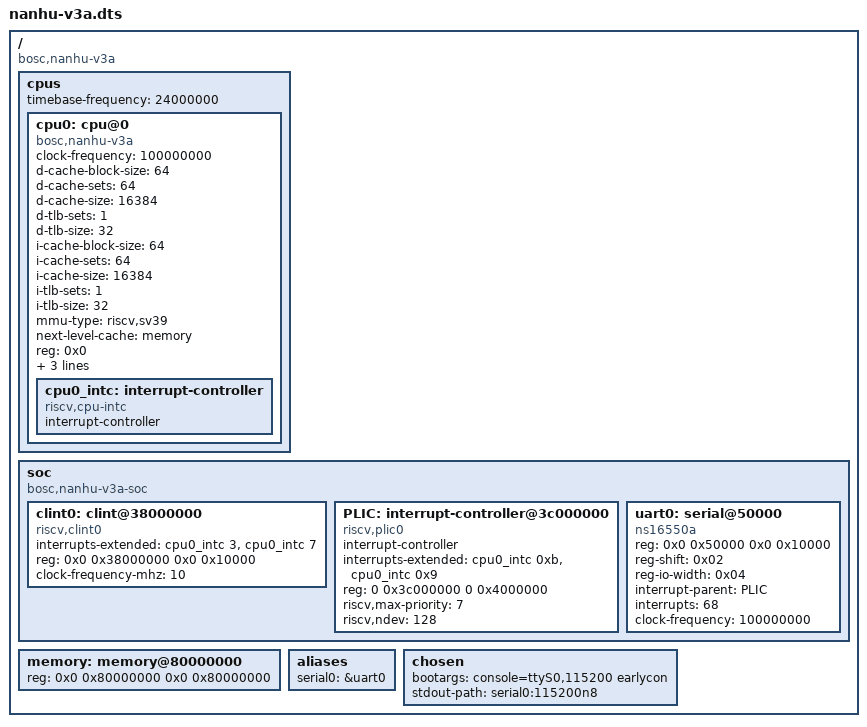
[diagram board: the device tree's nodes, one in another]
// SPDX-License-Identifier: (GPL-2.0 OR MIT)
/* Copyright (c) 2023-2024 BOSC */

/dts-v1/;

/ {
	#address-cells = <2>;
	#size-cells = <2>;
	compatible = "bosc,nanhu-v3a";

	cpus {
		#address-cells = <1>;
		#size-cells = <0>;
		timebase-frequency = <24000000>;//rtc is 1M

		cpu0: cpu@0 {
			clock-frequency = <100000000>;
			compatible = "bosc,nanhu-v3a", "riscv";
			d-cache-block-size = <64>;
			d-cache-sets = <64>;
			d-cache-size = <16384>;
			d-tlb-sets = <1>;
			d-tlb-size = <32>;
			device_type = "cpu";
			i-cache-block-size = <64>;
			i-cache-sets = <64>;
			i-cache-size = <16384>;
			i-tlb-sets = <1>;
			i-tlb-size = <32>;
			mmu-type = "riscv,sv39";
			next-level-cache = <&memory>;
			reg = <0x0>;
			riscv,isa = "rv64imafdcv";
			status = "okay";
			timebase-frequency = <24000000>;//rtc is 1M
			tlb-split;

			cpu0_intc: interrupt-controller {
				#interrupt-cells = <1>;
				compatible = "riscv,cpu-intc";
				interrupt-controller;
			};
		};

	//	cpu1: cpu@1 {
	//		clock-frequency = <0>;
	//		compatible = "bosc,nanhu-v3a", "riscv";
	//		d-cache-block-size = <64>;
	//		d-cache-sets = <64>;
	//		d-cache-size = <16384>;
	//		d-tlb-sets = <1>;
	//		d-tlb-size = <32>;
	//		device_type = "cpu";
	//		i-cache-block-size = <64>;
	//		i-cache-sets = <64>;
	//		i-cache-size = <16384>;
	//		i-tlb-sets = <1>;
	//		i-tlb-size = <32>;
	//		mmu-type = "riscv,sv39";
	//		next-level-cache = <&memory>;
	//		reg = <0x1>;
	//		riscv,isa = "rv64imafdc";
	//		status = "okay";
	//		timebase-frequency = <100000000>;//rtc is 1M
	//		tlb-split;

	//		cpu1_intc: interrupt-controller {
	//			#interrupt-cells = <1>;
	//			compatible = "riscv,cpu-intc";
	//			interrupt-controller;
	//		};
	//	};

	};

	soc {
		#address-cells = <2>;
		#size-cells = <2>;
		compatible = "bosc,nanhu-v3a-soc", "simple-bus";
		ranges;

		//debug_controller0: debug-controller@0 {
		//	compatible = "sifive,debug-013", "riscv,debug-013";
		//	interrupts-extended = <&cpu0_intc 65535>;
		//	reg = <0x0 0x0 0x0 0x1000>;
		//	reg-names = "control";
		//};

		clint0: clint@38000000 {
			compatible = "riscv,clint0";
			//interrupts-extended = <&cpu0_intc 3 &cpu0_intc 7 &cpu1_intc 3 &cpu1_intc 7>;
			interrupts-extended = <&cpu0_intc 3 &cpu0_intc 7>;
			reg = <0x0 0x38000000 0x0 0x10000>;
			reg-names = "control";
			clock-frequency-mhz = <10>;
		};

		PLIC: interrupt-controller@3c000000 {
			#interrupt-cells = <1>;
			compatible = "riscv,plic0";
			interrupt-controller;
			interrupts-extended = <&cpu0_intc 0xb &cpu0_intc 0x9>;
			reg = <0 0x3c000000 0 0x4000000>;
			reg-names = "control";
			riscv,max-priority = <7>;
			riscv,ndev = <128>;
		};

		// clkc: misc_clk_0 {
		// 	#clock-cells = <0>;
		// 	clock-frequency = <100000000>;
		// 	compatible = "fixed-clock";
		// };
		// clkb: misc_clk_1 {
		// 	#clock-cells = <0>;
		// 	clock-frequency = <25000000>;
		// 	compatible = "fixed-clock";
		// };
                  
                // ethernet1: ethernet@190000 {
                //         compatible = "st,stm32-dwmac", "snps,dwmac-3.50a";
                //         reg = <0 0x190000 0 0x10000>;
                //         reg-names = "stmmaceth";
                //         interrupt-parent = <&PLIC>;
                //         interrupts = <76 75 74>;
                //         interrupt-names = "eth_lpi", "macirq", "eth_wake_irq";
                //         clock-names = "stmmaceth";
                //         clocks = <&clkc>;
                //         //st,syscon = <&syscfg 0x4>;
                //         snps,pbl = <2>;
                //         snps,mixed-burst;
                //         phy-mode = "rgmii";
                //         // stmmac driver can not find phy if add this node
                //         //
                //         phy-handle = <&phy>;
                //             mdio {
                //                 #address-cells = <0x1>;
                //                 #size-cells = <0x0>;
                //                 phyaddr = <0x0>;
                //                 compatible = "snps,dwmac-mdio";
                //                 phy: phy@0 {
                //                 //phyaddr = <0x7>;
                //                 compatible = "marvell,88e1510";
                //                 device_type = "ethernet-phy";
                //                 reg = <0x0>;
                //             };
                //         };
                // };


        // sdhci2: sdhci@1200000 {
        //     compatible = "snps,dwcmshc-sdhci";
        //     reg = <0 0x1200000 0 0x10000>;
        //     interrupt-parent = <&PLIC>;
        //     interrupts = <77>;
        //     clocks = <&clkb>;
        //     clock-names = "core";
        //     sd-uhs-sdr12;
        //     no-1-8-v;
        //     disable-wp;
        //     broken-cd;
        //     bus-width = <4>;
        // };


		uart0: serial@50000 {
			compatible = "ns16550a";
			reg = <0x0 0x50000 0x0 0x10000>;
			reg-shift = <0x02>;
			reg-io-width = <0x04>;
			interrupt-parent = <&PLIC>;
			interrupts = <68>;
			clock-frequency = <100000000>;
			status = "okay";
		};
	};

	memory: memory@80000000 {
		device_type = "memory";
		reg = <0x0 0x80000000 0x0 0x80000000>;
	};
	aliases {
		serial0 = &uart0;
	};

	chosen {
		//bootargs = "root=/dev/nvme0n1p2 rootfstype=ext4 rw rootwait console=ttyS0 earlycon noinitrd";
		bootargs = "console=ttyS0,115200 earlycon";
		//bootargs = "root=/dev/nfs nfsroot=172.28.101.77:/Users/r00t/Workspace/riscv/v3a-nfs ip=172.28.101.76:172.28.102.175:172.28.100.1:255.255.252.0::eth0:dhcp  console=ttyS0,115200 earlycon";
		//bootargs = "bootargs root=/dev/nfs nfsroot=192.168.2.100:/home/user01/qinshaoqing/nfs-shared/rootfs ip=192.168.2.10:192.168.2.100:192.168.2.1:255.255.255.0::eth0:off  console=ttyS0,115200 earlycon";
		//bootargs = "bootargs root=/dev/nfs nfsroot=192.168.1.200:/home/user01/qinshaoqing/nfs-shared/1_5grootfs ip=192.168.1.10:192.168.1.200:192.168.1.1:255.255.255.0::eth0:off  console=ttyS0,115200 earlycon";
		//bootargs = "bootargs root=/dev/nfs nfsroot=192.168.1.200:/home/user01/qinshaoqing/nfs-shared/1_11_rootfs ip=192.168.1.11:192.168.1.200:192.168.1.1:255.255.255.0::eth0:off  console=ttyS0,115200 earlycon";
                //bootargs = "console=hvc0 earlycon=sbi";
		stdout-path = "serial0:115200n8";
	};
};
